VERSION ""

NS_ :

BS_:

BU_: BMS VCU GW

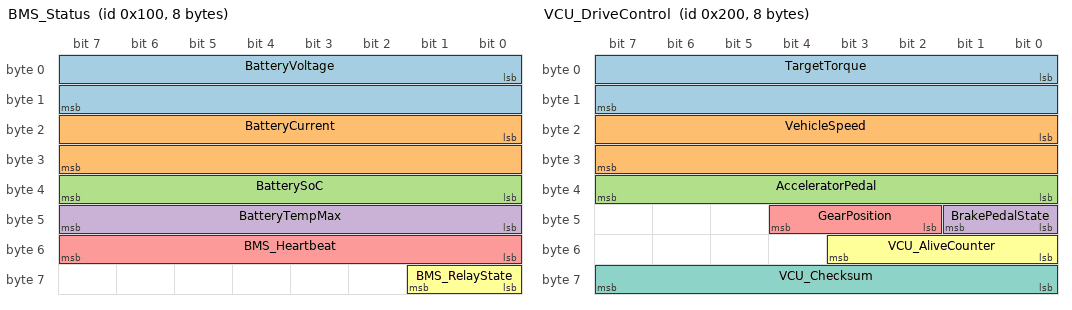
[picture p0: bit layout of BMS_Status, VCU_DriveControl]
BO_ 256 BMS_Status: 8 BMS
 SG_ BatteryVoltage : 0|16@1+ (0.1,0) [0|6553.5] "V" VCU,GW
 SG_ BatteryCurrent : 16|16@1- (0.1,0) [-3276.8|3276.7] "A" VCU,GW
 SG_ BatterySoC : 32|8@1+ (0.5,0) [0|100] "%" VCU,GW
 SG_ BatteryTempMax : 40|8@1+ (1,-40) [-40|215] "degC" VCU,GW
 SG_ BMS_Heartbeat : 48|8@1+ (1,0) [0|255] "" VCU,GW
 SG_ BMS_RelayState : 56|2@1+ (1,0) [0|3] "" VCU,GW

BO_ 512 VCU_DriveControl: 8 VCU
 SG_ TargetTorque : 0|16@1+ (0.5,0) [0|32767.5] "Nm" BMS,GW
 SG_ VehicleSpeed : 16|16@1+ (0.1,0) [0|6553.5] "km/h" BMS,GW
 SG_ AcceleratorPedal : 32|8@1+ (0.4,0) [0|100] "%" BMS,GW
 SG_ BrakePedalState : 40|2@1+ (1,0) [0|3] "" BMS,GW
 SG_ GearPosition : 42|3@1+ (1,0) [0|7] "" BMS,GW
 SG_ VCU_AliveCounter : 48|4@1+ (1,0) [0|15] "" BMS,GW
 SG_ VCU_Checksum : 56|8@1+ (1,0) [0|255] "" BMS,GW

CM_ BU_ BMS "Battery Management System ECU";
CM_ BU_ VCU "Vehicle Control Unit ECU";
CM_ BU_ GW "Central Gateway ECU";
CM_ BO_ 256 "BMS telemetry frame sent periodically every 50ms (ID 0x100)";
CM_ BO_ 512 "VCU powertrain control frame sent periodically every 20ms (ID 0x200)";
CM_ SG_ 256 BatteryCurrent "Negative: Discharge current, Positive: Charge current";
CM_ SG_ 512 TargetTorque "Demand torque sent to traction inverter";

BA_DEF_ BO_ "GenMsgCycleTime" INT 0 10000;
BA_DEF_ BO_ "GenMsgSendType" ENUM "Cyclic","Event","Mixed";

BA_DEF_DEF_ "GenMsgCycleTime" 100;
BA_DEF_DEF_ "GenMsgSendType" "Cyclic";

BA_ "GenMsgCycleTime" BO_ 256 50;
BA_ "GenMsgCycleTime" BO_ 512 20;
